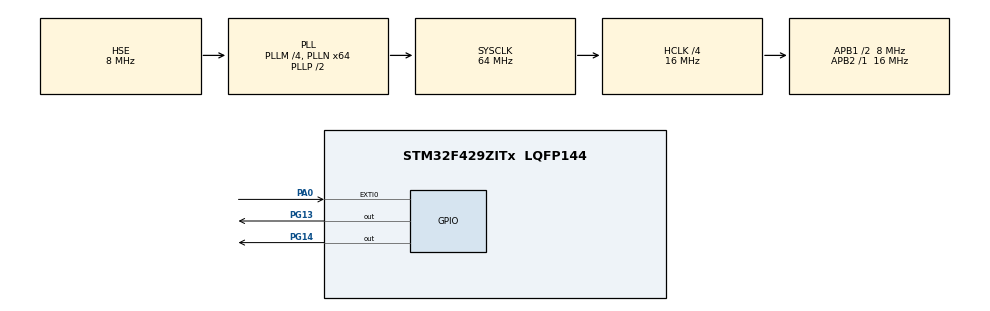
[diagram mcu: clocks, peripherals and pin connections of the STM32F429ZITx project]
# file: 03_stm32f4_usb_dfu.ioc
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Mcu.Family=STM32F4
Mcu.Name=STM32F429ZITx
Mcu.Package=LQFP144
NVIC.EXTI0_IRQn=true\:0\:0\:false\:false\:true\:true\:true
NVIC.PriorityGroup=NVIC_PRIORITYGROUP_4
PA0/WKUP.Signal=GPXTI0
PG13.Signal=GPIO_Output
PG14.Signal=GPIO_Output
PH0/OSC_IN.Mode=HSE-External-Oscillator
PH0/OSC_IN.Signal=RCC_OSC_IN
PH1/OSC_OUT.Mode=HSE-External-Oscillator
PH1/OSC_OUT.Signal=RCC_OSC_OUT
ProjectManager.HeapSize=0x200
ProjectManager.StackSize=0x400
ProjectManager.TargetToolchain=MDK-ARM V5.27
RCC.48MHZClocksFreq_Value=42666666.666666664
RCC.AHBCLKDivider=RCC_SYSCLK_DIV4
RCC.AHBFreq_Value=16000000
RCC.APB1CLKDivider=RCC_HCLK_DIV2
RCC.APB1Freq_Value=8000000
RCC.APB1TimFreq_Value=16000000
RCC.APB2Freq_Value=16000000
RCC.APB2TimFreq_Value=16000000
RCC.CortexFreq_Value=16000000
RCC.HCLKFreq_Value=16000000
RCC.HSE_VALUE=8000000
RCC.HSI_VALUE=16000000
RCC.LSE_VALUE=32768
RCC.PLLM=4
RCC.PLLN=64
RCC.PLLQ=3
RCC.PLLSourceVirtual=RCC_PLLSOURCE_HSE
RCC.SYSCLKFreq_VALUE=64000000
RCC.SYSCLKSource=RCC_SYSCLKSOURCE_PLLCLK
RCC.VCOOutputFreq_Value=128000000
board=custom

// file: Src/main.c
/* USER CODE BEGIN Header */
/**
  ******************************************************************************
  * @file           : main.c
  * @brief          : Main program body
  ******************************************************************************
  * @attention
  *
  * <h2><center>&copy; Copyright (c) 2020 STMicroelectronics.
  * All rights reserved.</center></h2>
  *
  * This software component is licensed by ST under Ultimate Liberty license
  * SLA0044, the "License"; You may not use this file except in compliance with
  * the License. You may obtain a copy of the License at:
  *                             www.st.com/SLA0044
  *
  ******************************************************************************
  */
/* USER CODE END Header */

#include "main.h"

/* USER CODE BEGIN PV */
#define LED_FLASH_INTERVAL 500 // mS

uint32_t bootloader_is_requested;  // this flag can be set to non-zero value anywhere
// in app. It is checked in main loop and
// , if set, calls Bootload_Reset()

uint32_t boot_check_var; // holds value to check on reset to see if bootloader
                         // has been requested
const uint32_t boot_special_value = 0xCAFEFEED;
const uint32_t boot_addr_stm32f4 = 0x8008000;
/* USER CODE END PV */

void SystemClock_Config(void);
static void MX_GPIO_Init(void);

/* USER CODE BEGIN 0 */
void HAL_GPIO_EXTI_Callback(uint16_t GPIO_Pin)
{
  /* Prevent unused argument(s) compilation warning */
  UNUSED(GPIO_Pin);
  /* NOTE: This function Should not be modified, when the callback is needed,
           the HAL_GPIO_EXTI_Callback could be implemented in the user file
   */
	bootloader_is_requested = 1;
}
/* USER CODE END 0 */

int main(void)
{
  /* USER CODE BEGIN 1 */
	uint32_t led_flash_ticks = 0;
  /* USER CODE END 1 */

  /* MCU Configuration--------------------------------------------------------*/

  /* Reset of all peripherals, Initializes the Flash interface and the Systick. */
  HAL_Init();

  /* Configure the system clock */
  SystemClock_Config();

  /* Initialize all configured peripherals */
  MX_GPIO_Init();

  /* Infinite loop */
  while (1)
  {

    /* USER CODE BEGIN 3 */

		if (HAL_GetTick() - led_flash_ticks > LED_FLASH_INTERVAL)
	   {
        HAL_GPIO_TogglePin(GPIOG, GPIO_PIN_13 | GPIO_PIN_14);
        led_flash_ticks = HAL_GetTick();
     }
		 if( bootloader_is_requested )
		 {
			 bootloader_is_requested = 0;
	     boot_check_var = boot_special_value;
       HAL_NVIC_SystemReset();
		}
  }
  /* USER CODE END 3 */
}

void SystemClock_Config(void)
{
  RCC_OscInitTypeDef RCC_OscInitStruct = {0};
  RCC_ClkInitTypeDef RCC_ClkInitStruct = {0};

  /** Configure the main internal regulator output voltage
  */
  __HAL_RCC_PWR_CLK_ENABLE();
  __HAL_PWR_VOLTAGESCALING_CONFIG(PWR_REGULATOR_VOLTAGE_SCALE3);
  /** Initializes the CPU, AHB and APB busses clocks
  */
  RCC_OscInitStruct.OscillatorType = RCC_OSCILLATORTYPE_HSE;
  RCC_OscInitStruct.HSEState = RCC_HSE_ON;
  RCC_OscInitStruct.PLL.PLLState = RCC_PLL_ON;
  RCC_OscInitStruct.PLL.PLLSource = RCC_PLLSOURCE_HSE;
  RCC_OscInitStruct.PLL.PLLM = 4;
  RCC_OscInitStruct.PLL.PLLN = 64;
  RCC_OscInitStruct.PLL.PLLP = RCC_PLLP_DIV2;
  RCC_OscInitStruct.PLL.PLLQ = 3;
  if (HAL_RCC_OscConfig(&RCC_OscInitStruct) != HAL_OK)
  {
    Error_Handler();
  }
  /** Initializes the CPU, AHB and APB busses clocks
  */
  RCC_ClkInitStruct.ClockType = RCC_CLOCKTYPE_HCLK|RCC_CLOCKTYPE_SYSCLK
                              |RCC_CLOCKTYPE_PCLK1|RCC_CLOCKTYPE_PCLK2;
  RCC_ClkInitStruct.SYSCLKSource = RCC_SYSCLKSOURCE_PLLCLK;
  RCC_ClkInitStruct.AHBCLKDivider = RCC_SYSCLK_DIV4;
  RCC_ClkInitStruct.APB1CLKDivider = RCC_HCLK_DIV2;
  RCC_ClkInitStruct.APB2CLKDivider = RCC_HCLK_DIV1;

  if (HAL_RCC_ClockConfig(&RCC_ClkInitStruct, FLASH_LATENCY_0) != HAL_OK)
  {
    Error_Handler();
  }
}

static void MX_GPIO_Init(void)
{
  GPIO_InitTypeDef GPIO_InitStruct = {0};

  /* GPIO Ports Clock Enable */
  __HAL_RCC_GPIOH_CLK_ENABLE();
  __HAL_RCC_GPIOA_CLK_ENABLE();
  __HAL_RCC_GPIOG_CLK_ENABLE();

  /*Configure GPIO pin Output Level */
  HAL_GPIO_WritePin(GPIOG, GPIO_PIN_13|GPIO_PIN_14, GPIO_PIN_RESET);

  /*Configure GPIO pin : PA0 */
  GPIO_InitStruct.Pin = GPIO_PIN_0;
  GPIO_InitStruct.Mode = GPIO_MODE_IT_RISING;
  GPIO_InitStruct.Pull = GPIO_NOPULL;
  HAL_GPIO_Init(GPIOA, &GPIO_InitStruct);

  /*Configure GPIO pins : PG13 PG14 */
  GPIO_InitStruct.Pin = GPIO_PIN_13|GPIO_PIN_14;
  GPIO_InitStruct.Mode = GPIO_MODE_OUTPUT_PP;
  GPIO_InitStruct.Pull = GPIO_NOPULL;
  GPIO_InitStruct.Speed = GPIO_SPEED_FREQ_LOW;
  HAL_GPIO_Init(GPIOG, &GPIO_InitStruct);

  /* EXTI interrupt init*/
  HAL_NVIC_SetPriority(EXTI0_IRQn, 0, 0);
  HAL_NVIC_EnableIRQ(EXTI0_IRQn);

}

void Error_Handler(void)
{
}

/************************ (C) COPYRIGHT STMicroelectronics *****END OF FILE****/
